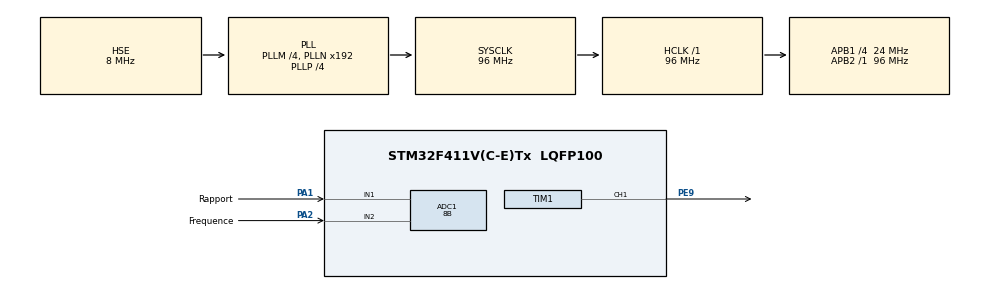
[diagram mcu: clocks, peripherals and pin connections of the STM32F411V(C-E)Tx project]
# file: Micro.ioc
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ADC1.Channel-0\#ChannelRegularConversion=ADC_CHANNEL_1
ADC1.Channel-2\#ChannelRegularConversion=ADC_CHANNEL_2
ADC1.ContinuousConvMode=ENABLE
ADC1.EOCSelection=ADC_EOC_SINGLE_CONV
ADC1.InjNumberOfConversion=0
ADC1.NbrOfConversion=2
ADC1.NbrOfConversionFlag=1
ADC1.Rank-0\#ChannelRegularConversion=1
ADC1.Rank-2\#ChannelRegularConversion=2
ADC1.Resolution=ADC_RESOLUTION_8B
ADC1.SamplingTime-0\#ChannelRegularConversion=ADC_SAMPLETIME_15CYCLES
ADC1.SamplingTime-2\#ChannelRegularConversion=ADC_SAMPLETIME_15CYCLES
ADC1.master=1
Mcu.Family=STM32F4
Mcu.Name=STM32F411V(C-E)Tx
Mcu.Package=LQFP100
NVIC.PriorityGroup=NVIC_PRIORITYGROUP_0
PA1.GPIO_Label=Rapport
PA1.Signal=ADCx_IN1
PA2.GPIO_Label=Frequence
PA2.Signal=ADCx_IN2
PE9.GPIO_PuPd=GPIO_PULLDOWN
PE9.GPIO_Speed=GPIO_SPEED_FREQ_VERY_HIGH
PE9.Signal=S_TIM1_CH1
PH0\ -\ OSC_IN.Mode=HSE-External-Oscillator
PH0\ -\ OSC_IN.Signal=RCC_OSC_IN
PH1\ -\ OSC_OUT.Mode=HSE-External-Oscillator
PH1\ -\ OSC_OUT.Signal=RCC_OSC_OUT
ProjectManager.HeapSize=0x200
ProjectManager.StackSize=0x400
ProjectManager.TargetToolchain=STM32CubeIDE
RCC.48MHZClocksFreq_Value=48000000
RCC.AHBFreq_Value=96000000
RCC.APB1CLKDivider=RCC_HCLK_DIV4
RCC.APB1Freq_Value=24000000
RCC.APB1TimFreq_Value=48000000
RCC.APB2Freq_Value=96000000
RCC.APB2TimFreq_Value=96000000
RCC.CortexFreq_Value=96000000
RCC.HCLKFreq_Value=96000000
RCC.HSE_VALUE=8000000
RCC.HSI_VALUE=16000000
RCC.PLLI2SM=5
RCC.PLLI2SN=200
RCC.PLLM=4
RCC.PLLP=RCC_PLLP_DIV4
RCC.PLLQ=8
RCC.PLLSourceVirtual=RCC_PLLSOURCE_HSE
RCC.SYSCLKFreq_VALUE=96000000
RCC.SYSCLKSource=RCC_SYSCLKSOURCE_PLLCLK
RCC.VCOOutputFreq_Value=384000000
SH.ADCx_IN1.0=ADC1_IN1,IN1
SH.ADCx_IN2.0=ADC1_IN2,IN2
SH.S_TIM1_CH1.0=TIM1_CH1,PWM Generation1 CH1
TIM1.Channel-PWM\ Generation1\ CH1=TIM_CHANNEL_1
TIM1.ClockDivision=TIM_CLOCKDIVISION_DIV4
TIM1.OCIdleState_1=TIM_OCIDLESTATE_SET
TIM1.Period=100
TIM1.Prescaler=94
TIM1.Pulse-PWM\ Generation1\ CH1=20
VP_TIM1_VS_ClockSourceINT.Mode=Internal
board=STM32F411E-DISCO

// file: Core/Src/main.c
/* USER CODE BEGIN Header */
/**
  ******************************************************************************
  * @file           : main.c
  * @brief          : Main program body
  ******************************************************************************
  * @attention
  *
  * <h2><center>&copy; Copyright (c) 2021 STMicroelectronics.
  * All rights reserved.</center></h2>
  *
  * This software component is licensed by ST under Ultimate Liberty license
  * SLA0044, the "License"; You may not use this file except in compliance with
  * the License. You may obtain a copy of the License at:
  *                             www.st.com/SLA0044
  *
  ******************************************************************************
  */
/* USER CODE END Header */
#include "main.h"

ADC_HandleTypeDef hadc1;

TIM_HandleTypeDef htim1;

/* USER CODE BEGIN PV */
ADC_ChannelConfTypeDef sConfig = {0};
TIM_OC_InitTypeDef sConfigOC = {0};
TIM_ClockConfigTypeDef sClockSourceConfig = {0};
uint8_t conversion1=0; // Pour stocker la valeur de la conversion du canal1 du ADC1
uint8_t conversion2=0; //Pour stocker la valeur de la converion du canal2 du ADC1
uint16_t Time_Periode=0;
uint16_t frequence=0;
float pulse=0.0;

/* USER CODE END PV */

void SystemClock_Config(void);
static void MX_GPIO_Init(void);
static void MX_TIM1_Init(void);
static void MX_ADC1_Init(void);
/* USER CODE BEGIN PFP */
uint8_t convert_channel(int canal);
/* USER CODE END PFP */

int main(void)
{

  /* MCU Configuration--------------------------------------------------------*/

  /* Reset of all peripherals, Initializes the Flash interface and the Systick. */
  HAL_Init();

  /* Configure the system clock */
  SystemClock_Config();

  /* Initialize all configured peripherals */
  MX_GPIO_Init();
  MX_TIM1_Init();
  MX_ADC1_Init();
  /* USER CODE BEGIN 2 */

  HAL_TIM_OC_Start(&htim1, TIM_CHANNEL_1);
  HAL_TIM_PWM_Start(&htim1, TIM_CHANNEL_1);

  /* USER CODE END 2 */

  /* Infinite loop */
  while (1)
  {

    /* USER CODE BEGIN 3 */
	  conversion1=convert_channel(1);//Pour avoir un rapport cyclique entre 0 et 1000%
	  conversion2=convert_channel(2); //Pour avoir un plage de frequence entre 0 et 1
	  frequence=(9000/255)*conversion2+1000;
	  Time_Periode=SystemCoreClock/(frequence*(htim1.Init.Prescaler+1));
	  pulse=(((conversion1)*Time_Periode)/255);
	  htim1.Init.Period=Time_Periode;
	  sConfigOC.Pulse=pulse;

	  HAL_TIM_Base_Init(&htim1);
	  HAL_TIM_OC_Init(&htim1);
	  HAL_TIM_PWM_Init(&htim1);
	  HAL_TIM_PWM_ConfigChannel(&htim1, &sConfigOC, TIM_CHANNEL_1);
	  HAL_TIM_OC_Start(&htim1, TIM_CHANNEL_1);
	  HAL_TIM_PWM_Start(&htim1, TIM_CHANNEL_1);

  }
  /* USER CODE END 3 */
}

void SystemClock_Config(void)
{
  RCC_OscInitTypeDef RCC_OscInitStruct = {0};
  RCC_ClkInitTypeDef RCC_ClkInitStruct = {0};

  /** Configure the main internal regulator output voltage
  */
  __HAL_RCC_PWR_CLK_ENABLE();
  __HAL_PWR_VOLTAGESCALING_CONFIG(PWR_REGULATOR_VOLTAGE_SCALE1);
  /** Initializes the RCC Oscillators according to the specified parameters
  * in the RCC_OscInitTypeDef structure.
  */
  RCC_OscInitStruct.OscillatorType = RCC_OSCILLATORTYPE_HSE;
  RCC_OscInitStruct.HSEState = RCC_HSE_ON;
  RCC_OscInitStruct.PLL.PLLState = RCC_PLL_ON;
  RCC_OscInitStruct.PLL.PLLSource = RCC_PLLSOURCE_HSE;
  RCC_OscInitStruct.PLL.PLLM = 4;
  RCC_OscInitStruct.PLL.PLLN = 192;
  RCC_OscInitStruct.PLL.PLLP = RCC_PLLP_DIV4;
  RCC_OscInitStruct.PLL.PLLQ = 8;
  if (HAL_RCC_OscConfig(&RCC_OscInitStruct) != HAL_OK)
  {
    Error_Handler();
  }
  /** Initializes the CPU, AHB and APB buses clocks
  */
  RCC_ClkInitStruct.ClockType = RCC_CLOCKTYPE_HCLK|RCC_CLOCKTYPE_SYSCLK
                              |RCC_CLOCKTYPE_PCLK1|RCC_CLOCKTYPE_PCLK2;
  RCC_ClkInitStruct.SYSCLKSource = RCC_SYSCLKSOURCE_PLLCLK;
  RCC_ClkInitStruct.AHBCLKDivider = RCC_SYSCLK_DIV1;
  RCC_ClkInitStruct.APB1CLKDivider = RCC_HCLK_DIV4;
  RCC_ClkInitStruct.APB2CLKDivider = RCC_HCLK_DIV1;

  if (HAL_RCC_ClockConfig(&RCC_ClkInitStruct, FLASH_LATENCY_3) != HAL_OK)
  {
    Error_Handler();
  }
}

static void MX_ADC1_Init(void)
{

  ADC_ChannelConfTypeDef sConfig = {0};

  /** Configure the global features of the ADC (Clock, Resolution, Data Alignment and number of conversion)
  */
  hadc1.Instance = ADC1;
  hadc1.Init.ClockPrescaler = ADC_CLOCK_SYNC_PCLK_DIV4;
  hadc1.Init.Resolution = ADC_RESOLUTION_8B;
  hadc1.Init.ScanConvMode = ENABLE;
  hadc1.Init.ContinuousConvMode = ENABLE;
  hadc1.Init.DiscontinuousConvMode = DISABLE;
  hadc1.Init.ExternalTrigConvEdge = ADC_EXTERNALTRIGCONVEDGE_NONE;
  hadc1.Init.ExternalTrigConv = ADC_SOFTWARE_START;
  hadc1.Init.DataAlign = ADC_DATAALIGN_RIGHT;
  hadc1.Init.NbrOfConversion = 2;
  hadc1.Init.DMAContinuousRequests = DISABLE;
  hadc1.Init.EOCSelection = ADC_EOC_SINGLE_CONV;
  if (HAL_ADC_Init(&hadc1) != HAL_OK)
  {
    Error_Handler();
  }
  /** Configure for the selected ADC regular channel its corresponding rank in the sequencer and its sample time.
  */
  sConfig.Channel = ADC_CHANNEL_1;
  sConfig.Rank = 1;
  sConfig.SamplingTime = ADC_SAMPLETIME_15CYCLES;
  if (HAL_ADC_ConfigChannel(&hadc1, &sConfig) != HAL_OK)
  {
    Error_Handler();
  }
  /** Configure for the selected ADC regular channel its corresponding rank in the sequencer and its sample time.
  */
  sConfig.Channel = ADC_CHANNEL_2;
  sConfig.Rank = 2;
  if (HAL_ADC_ConfigChannel(&hadc1, &sConfig) != HAL_OK)
  {
    Error_Handler();
  }

}

static void MX_TIM1_Init(void)
{

  TIM_ClockConfigTypeDef sClockSourceConfig = {0};
  TIM_MasterConfigTypeDef sMasterConfig = {0};

  TIM_BreakDeadTimeConfigTypeDef sBreakDeadTimeConfig = {0};

  htim1.Instance = TIM1;
  htim1.Init.Prescaler = 94;
  htim1.Init.CounterMode = TIM_COUNTERMODE_UP;
  htim1.Init.Period = 100;
  htim1.Init.ClockDivision = TIM_CLOCKDIVISION_DIV4;
  htim1.Init.RepetitionCounter = 0;
  htim1.Init.AutoReloadPreload = TIM_AUTORELOAD_PRELOAD_DISABLE;
  if (HAL_TIM_Base_Init(&htim1) != HAL_OK)
  {
    Error_Handler();
  }
  sClockSourceConfig.ClockSource = TIM_CLOCKSOURCE_INTERNAL;
  if (HAL_TIM_ConfigClockSource(&htim1, &sClockSourceConfig) != HAL_OK)
  {
    Error_Handler();
  }
  if (HAL_TIM_PWM_Init(&htim1) != HAL_OK)
  {
    Error_Handler();
  }
  sMasterConfig.MasterOutputTrigger = TIM_TRGO_RESET;
  sMasterConfig.MasterSlaveMode = TIM_MASTERSLAVEMODE_DISABLE;
  if (HAL_TIMEx_MasterConfigSynchronization(&htim1, &sMasterConfig) != HAL_OK)
  {
    Error_Handler();
  }
  sConfigOC.OCMode = TIM_OCMODE_PWM1;
  sConfigOC.Pulse = 20;
  sConfigOC.OCPolarity = TIM_OCPOLARITY_HIGH;
  sConfigOC.OCNPolarity = TIM_OCNPOLARITY_HIGH;
  sConfigOC.OCFastMode = TIM_OCFAST_DISABLE;
  sConfigOC.OCIdleState = TIM_OCIDLESTATE_SET;
  sConfigOC.OCNIdleState = TIM_OCNIDLESTATE_RESET;
  if (HAL_TIM_PWM_ConfigChannel(&htim1, &sConfigOC, TIM_CHANNEL_1) != HAL_OK)
  {
    Error_Handler();
  }
  sBreakDeadTimeConfig.OffStateRunMode = TIM_OSSR_DISABLE;
  sBreakDeadTimeConfig.OffStateIDLEMode = TIM_OSSI_DISABLE;
  sBreakDeadTimeConfig.LockLevel = TIM_LOCKLEVEL_OFF;
  sBreakDeadTimeConfig.DeadTime = 0;
  sBreakDeadTimeConfig.BreakState = TIM_BREAK_DISABLE;
  sBreakDeadTimeConfig.BreakPolarity = TIM_BREAKPOLARITY_HIGH;
  sBreakDeadTimeConfig.AutomaticOutput = TIM_AUTOMATICOUTPUT_DISABLE;
  if (HAL_TIMEx_ConfigBreakDeadTime(&htim1, &sBreakDeadTimeConfig) != HAL_OK)
  {
    Error_Handler();
  }
  HAL_TIM_MspPostInit(&htim1);

}

static void MX_GPIO_Init(void)
{

  /* GPIO Ports Clock Enable */
  __HAL_RCC_GPIOH_CLK_ENABLE();
  __HAL_RCC_GPIOA_CLK_ENABLE();
  __HAL_RCC_GPIOE_CLK_ENABLE();

}

/* USER CODE BEGIN 4 */
uint8_t convert_channel(int canal)
{
	uint8_t valeur; //stocker la valeur de la conversion
		if(canal==1)
		{
			sConfig.Channel=ADC_CHANNEL_1;//La converion est sur le canal1
			HAL_ADC_ConfigChannel(&hadc1, &sConfig);
			HAL_ADC_Start(&hadc1);//debut de la convetrsion

		}
		if(canal==2)
		{
			sConfig.Channel=ADC_CHANNEL_2;//la conversion est sur le canal2
			HAL_ADC_ConfigChannel(&hadc1, &sConfig);
			HAL_ADC_Start(&hadc1);//Debut de la conversion
		}

		if(HAL_ADC_PollForConversion(&hadc1, 1000)==HAL_OK)
		{
			valeur =(uint8_t)HAL_ADC_GetValue(&hadc1);
		}
	return valeur; // On retourne la valeur de la conversion
}

/* USER CODE END 4 */

void Error_Handler(void)
{
  __disable_irq();
  while (1)
  {
  }
}

/************************ (C) COPYRIGHT STMicroelectronics *****END OF FILE****/
